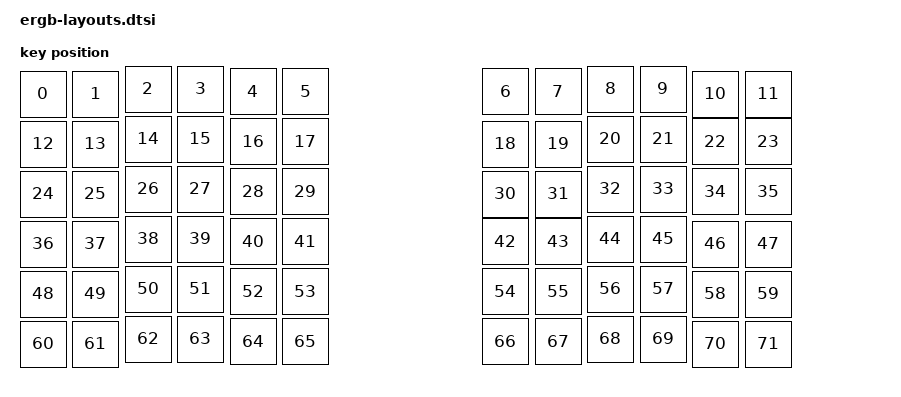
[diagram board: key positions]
#include <physical_layouts.dtsi>
/ {
	default_layout: default_layout {
	  compatible = "zmk,physical-layout";
	  display-name = "Default layout";
	  transform = <&default_transform>;
	  keys
		= <&key_physical_attrs 100 100    0   20       0     0     0>
        , <&key_physical_attrs 100 100  105   20       0     0     0>
		, <&key_physical_attrs 100 100  210   10       0     0     0>
		, <&key_physical_attrs 100 100  315   10       0     0     0>
		, <&key_physical_attrs 100 100  420   15       0     0     0>
		, <&key_physical_attrs 100 100  525	  15       0     0     0>
		, <&key_physical_attrs 100 100  925	  15	   0     0     0>
		, <&key_physical_attrs 100 100  1030  15	   0     0     0>
		, <&key_physical_attrs 100 100  1135  10       0     0     0>
		, <&key_physical_attrs 100 100  1240  10       0     0     0>
		, <&key_physical_attrs 100 100  1345  20       0     0     0>
        , <&key_physical_attrs 100 100  1450  20	   0     0     0>
		, <&key_physical_attrs 100 100  0	  120      0     0     0>
		, <&key_physical_attrs 100 100  105   120      0     0     0>
		, <&key_physical_attrs 100 100  210   110      0     0     0>
		, <&key_physical_attrs 100 100  315   110      0     0     0>
		, <&key_physical_attrs 100 100  420   115      0     0     0>
		, <&key_physical_attrs 100 100  525   115      0     0     0>
		, <&key_physical_attrs 100 100  925	  120      0     0     0>
		, <&key_physical_attrs 100 100  1030  120      0     0     0>
		, <&key_physical_attrs 100 100  1135  110      0     0     0>
        , <&key_physical_attrs 100 100  1240  110      0     0     0>
		, <&key_physical_attrs 100 100  1345  115      0     0     0>
		, <&key_physical_attrs 100 100  1450  115      0     0     0>
		, <&key_physical_attrs 100 100  0     220      0     0     0>
		, <&key_physical_attrs 100 100  105   220      0     0     0>
		, <&key_physical_attrs 100 100  210   210      0     0     0>
		, <&key_physical_attrs 100 100  315   210      0     0     0>
		, <&key_physical_attrs 100 100  420   215      0     0     0>
		, <&key_physical_attrs 100 100  525   215      0     0     0>
		, <&key_physical_attrs 100 100  925   220	   0     0     0>
        , <&key_physical_attrs 100 100  1030  220      0     0     0>
		, <&key_physical_attrs 100 100  1135  210      0     0     0>
		, <&key_physical_attrs 100 100  1240  210      0     0     0>
		, <&key_physical_attrs 100 100  1345  215      0     0     0>
		, <&key_physical_attrs 100 100  1450  215      0     0     0>
		, <&key_physical_attrs 100 100  0     320      0     0     0>
		, <&key_physical_attrs 100 100  105   320      0     0     0>
		, <&key_physical_attrs 100 100  210   310      0     0     0>
		, <&key_physical_attrs 100 100  315   310      0     0     0>
		, <&key_physical_attrs 100 100  420   315      0     0     0>
        , <&key_physical_attrs 100 100  525   315	   0     0     0>
		, <&key_physical_attrs 100 100  925   315       0     0     0>
		, <&key_physical_attrs 100 100  1030  315       0     0     0>
		, <&key_physical_attrs 100 100  1135  310       0     0     0>
		, <&key_physical_attrs 100 100  1240  310       0     0     0>
		, <&key_physical_attrs 100 100  1345  320       0     0     0>
		, <&key_physical_attrs 100 100  1450  320       0     0     0>
		, <&key_physical_attrs 100 100  0     420       0     0     0>
		, <&key_physical_attrs 100 100  105   420       0     0     0>
		, <&key_physical_attrs 100 100  210   410       0     0     0>
        , <&key_physical_attrs 100 100  315   410       0     0     0>
		, <&key_physical_attrs 100 100  420   415       0     0     0>
		, <&key_physical_attrs 100 100  525   415       0     0     0>
		, <&key_physical_attrs 100 100  925   415       0     0     0>
		, <&key_physical_attrs 100 100  1030  415       0     0     0>
		, <&key_physical_attrs 100 100  1135  410       0     0     0>
		, <&key_physical_attrs 100 100  1240  410       0     0     0>
		, <&key_physical_attrs 100 100  1345  420       0     0     0>
		, <&key_physical_attrs 100 100  1450  420       0     0     0>
	   	, <&key_physical_attrs 100 100  0     520       0     0     0>
		, <&key_physical_attrs 100 100  105   520       0     0     0>
		, <&key_physical_attrs 100 100  210   510       0     0     0>
        , <&key_physical_attrs 100 100  315   510       0     0     0>
		, <&key_physical_attrs 100 100  420   515       0     0     0>
		, <&key_physical_attrs 100 100  525   515       0     0     0>
		, <&key_physical_attrs 100 100  925   515       0     0     0>
		, <&key_physical_attrs 100 100  1030  515       0     0     0>
		, <&key_physical_attrs 100 100  1135  510       0     0     0>
		, <&key_physical_attrs 100 100  1240  510       0     0     0>
		, <&key_physical_attrs 100 100  1345  520       0     0     0>
		, <&key_physical_attrs 100 100  1450  520       0     0     0>
		;
	};
};
